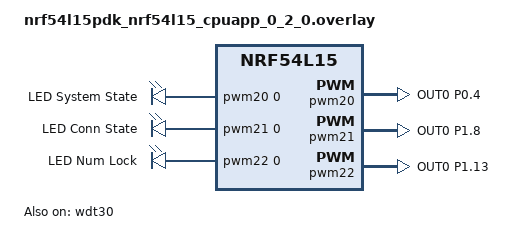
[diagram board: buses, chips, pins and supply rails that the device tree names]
/*
 * Copyright (c) 2024 Nordic Semiconductor ASA
 *
 * SPDX-License-Identifier: LicenseRef-Nordic-5-Clause
 */

/* For nRF54L, watchdog status is disabled by default. Needs to be enabled in DTS overlay. */
&wdt30 {
	status = "okay";
};

/ {
	pwmleds0 {
		compatible = "pwm-leds";
		status = "okay";

		pwm_led0: led_pwm_0 {
			status = "okay";
			pwms = <&pwm20 0 PWM_MSEC(20) PWM_POLARITY_NORMAL>;
			label = "LED System State";
		};
	};

	pwmleds1 {
		compatible = "pwm-leds";
		status = "okay";

		pwm_led1: led_pwm_1 {
			status = "okay";
			pwms = <&pwm21 0 PWM_MSEC(20) PWM_POLARITY_NORMAL>;
			label = "LED Conn State";
		};
	};

	pwmleds2 {
		compatible = "pwm-leds";
		status = "okay";

		pwm_led2: led_pwm_2 {
			status = "okay";
			pwms = <&pwm22 0 PWM_MSEC(20) PWM_POLARITY_NORMAL>;
			label = "LED Num Lock";
		};
	};
};

&pwm20 {
	status = "okay";
	pinctrl-0 = <&pwm20_default_alt>;
	pinctrl-1 = <&pwm20_sleep_alt>;
	pinctrl-names = "default", "sleep";
};

&pwm21 {
	status = "okay";
	pinctrl-0 = <&pwm21_default_alt>;
	pinctrl-1 = <&pwm21_sleep_alt>;
	pinctrl-names = "default", "sleep";
};

&pwm22 {
	status = "okay";
	pinctrl-0 = <&pwm22_default_alt>;
	pinctrl-1 = <&pwm22_sleep_alt>;
	pinctrl-names = "default", "sleep";
};

&pinctrl {
	pwm20_default_alt: pwm20_default_alt {
		group1 {
			psels = <NRF_PSEL(PWM_OUT0, 0, 4)>;
		};
	};

	pwm20_sleep_alt: pwm20_sleep_alt {
		group1 {
			psels = <NRF_PSEL(PWM_OUT0, 0, 4)>;
			low-power-enable;
		};
	};

	pwm21_default_alt: pwm21_default_alt {
		group1 {
			psels = <NRF_PSEL(PWM_OUT0, 1, 8)>;
		};
	};

	pwm21_sleep_alt: pwm21_sleep_alt {
		group1 {
			psels = <NRF_PSEL(PWM_OUT0, 1, 8)>;
			low-power-enable;
		};
	};

	pwm22_default_alt: pwm22_default_alt {
		group1 {
			psels = <NRF_PSEL(PWM_OUT0, 1, 13)>;
		};
	};

	pwm22_sleep_alt: pwm22_sleep_alt {
		group1 {
			psels = <NRF_PSEL(PWM_OUT0, 1, 13)>;
			low-power-enable;
		};
	};
};
